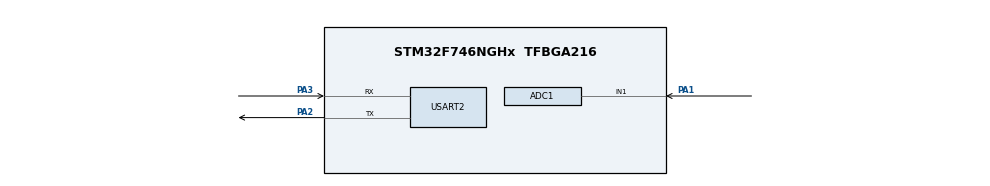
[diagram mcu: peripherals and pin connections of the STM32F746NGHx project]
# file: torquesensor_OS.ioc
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ADC1.Channel-0\#ChannelRegularConversion=ADC_CHANNEL_1
ADC1.NbrOfConversionFlag=1
ADC1.Rank-0\#ChannelRegularConversion=1
ADC1.SamplingTime-0\#ChannelRegularConversion=ADC_SAMPLETIME_3CYCLES
ADC1.master=1
FREERTOS.BinarySemaphores01=myBinarySem01,Dynamic,NULL
FREERTOS.Queues01=xTorqueSensorQueue,10,float,0,Dynamic,NULL,NULL
FREERTOS.Tasks01=vTaskReadTorque,0,128,TaskReadTorqueSensor,Default,NULL,Dynamic,NULL,NULL;vTaskMain,0,128,TaskMain,Default,NULL,Dynamic,NULL,NULL
Mcu.Family=STM32F7
Mcu.Name=STM32F746NGHx
Mcu.Package=TFBGA216
NVIC.PriorityGroup=NVIC_PRIORITYGROUP_4
PA1.Signal=ADCx_IN1
PA2.Mode=Asynchronous
PA2.Signal=USART2_TX
PA3.Mode=Asynchronous
PA3.Signal=USART2_RX
ProjectManager.HeapSize=0x200
ProjectManager.StackSize=0x400
ProjectManager.TargetToolchain=STM32CubeIDE
RCC.HSE_VALUE=25000000
RCC.HSI_VALUE=16000000
RCC.LSE_VALUE=32768
RCC.USBFreq_Value=96000000
RCC.VCOOutputFreq_Value=192000000
SH.ADCx_IN1.0=ADC1_IN1,IN1
USART2.VirtualMode-Asynchronous=VM_ASYNC
VP_FREERTOS_VS_CMSIS_V1.Mode=CMSIS_V1
board=custom

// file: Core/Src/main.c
/* USER CODE BEGIN Header */
/**
  ******************************************************************************
  * @file           : main.c
  * @brief          : Main program body
  ******************************************************************************
  * @attention
  *
  * Copyright (c) 2024 STMicroelectronics.
  * All rights reserved.
  *
  * This software is licensed under terms that can be found in the LICENSE file
  * in the root directory of this software component.
  * If no LICENSE file comes with this software, it is provided AS-IS.
  *
  ******************************************************************************
  */
/* USER CODE END Header */
#include "main.h"
#include "cmsis_os.h"
#include <stdio.h>
#include <string.h>

ADC_HandleTypeDef hadc1;

UART_HandleTypeDef huart2;

osThreadId vTaskReadTorqueHandle;
osThreadId vTaskMainHandle;
osMessageQId xTorqueSensorQueueHandle;
osSemaphoreId myBinarySem01Handle;

void SystemClock_Config(void);
static void MPU_Config(void);
static void MX_GPIO_Init(void);
static void MX_ADC1_Init(void);
static void MX_USART2_UART_Init(void);
void TaskReadTorqueSensor(void const * argument);
void TaskMain(void const * argument);

int main(void)
{

  /* MPU Configuration--------------------------------------------------------*/
  MPU_Config();

  /* MCU Configuration--------------------------------------------------------*/

  /* Reset of all peripherals, Initializes the Flash interface and the Systick. */
  HAL_Init();

  /* Configure the system clock */
  SystemClock_Config();

  /* Initialize all configured peripherals */
  MX_GPIO_Init();
  MX_ADC1_Init();
  MX_USART2_UART_Init();

  /* Create the semaphores(s) */
  /* definition and creation of myBinarySem01 */
  osSemaphoreDef(myBinarySem01);
  myBinarySem01Handle = osSemaphoreCreate(osSemaphore(myBinarySem01), 1);

  /* Create the queue(s) */
  /* definition and creation of xTorqueSensorQueue */
  osMessageQDef(xTorqueSensorQueue, 10, float);
  xTorqueSensorQueueHandle = osMessageCreate(osMessageQ(xTorqueSensorQueue), NULL);

  /* Create the thread(s) */
  /* definition and creation of vTaskReadTorque */
  osThreadDef(vTaskReadTorque, TaskReadTorqueSensor, osPriorityNormal, 0, 128);
  vTaskReadTorqueHandle = osThreadCreate(osThread(vTaskReadTorque), NULL);

  /* definition and creation of vTaskMain */
  osThreadDef(vTaskMain, TaskMain, osPriorityNormal, 0, 128);
  vTaskMainHandle = osThreadCreate(osThread(vTaskMain), NULL);

  /* Start scheduler */
  osKernelStart();

  /* We should never get here as control is now taken by the scheduler */
  /* Infinite loop */
  while (1)
  {

  }
}

void SystemClock_Config(void)
{
  RCC_OscInitTypeDef RCC_OscInitStruct = {0};
  RCC_ClkInitTypeDef RCC_ClkInitStruct = {0};

  /** Configure the main internal regulator output voltage
  */
  __HAL_RCC_PWR_CLK_ENABLE();
  __HAL_PWR_VOLTAGESCALING_CONFIG(PWR_REGULATOR_VOLTAGE_SCALE3);

  /** Initializes the RCC Oscillators according to the specified parameters
  * in the RCC_OscInitTypeDef structure.
  */
  RCC_OscInitStruct.OscillatorType = RCC_OSCILLATORTYPE_HSI;
  RCC_OscInitStruct.HSIState = RCC_HSI_ON;
  RCC_OscInitStruct.HSICalibrationValue = RCC_HSICALIBRATION_DEFAULT;
  RCC_OscInitStruct.PLL.PLLState = RCC_PLL_NONE;
  if (HAL_RCC_OscConfig(&RCC_OscInitStruct) != HAL_OK)
  {
    Error_Handler();
  }

  /** Initializes the CPU, AHB and APB buses clocks
  */
  RCC_ClkInitStruct.ClockType = RCC_CLOCKTYPE_HCLK|RCC_CLOCKTYPE_SYSCLK
                              |RCC_CLOCKTYPE_PCLK1|RCC_CLOCKTYPE_PCLK2;
  RCC_ClkInitStruct.SYSCLKSource = RCC_SYSCLKSOURCE_HSI;
  RCC_ClkInitStruct.AHBCLKDivider = RCC_SYSCLK_DIV1;
  RCC_ClkInitStruct.APB1CLKDivider = RCC_HCLK_DIV1;
  RCC_ClkInitStruct.APB2CLKDivider = RCC_HCLK_DIV1;

  if (HAL_RCC_ClockConfig(&RCC_ClkInitStruct, FLASH_LATENCY_0) != HAL_OK)
  {
    Error_Handler();
  }
}

static void MX_ADC1_Init(void)
{

  ADC_ChannelConfTypeDef sConfig = {0};

  /** Configure the global features of the ADC (Clock, Resolution, Data Alignment and number of conversion)
  */
  hadc1.Instance = ADC1;
  hadc1.Init.ClockPrescaler = ADC_CLOCK_SYNC_PCLK_DIV2;
  hadc1.Init.Resolution = ADC_RESOLUTION_12B;
  hadc1.Init.ScanConvMode = ADC_SCAN_DISABLE;
  hadc1.Init.ContinuousConvMode = DISABLE;
  hadc1.Init.DiscontinuousConvMode = DISABLE;
  hadc1.Init.ExternalTrigConvEdge = ADC_EXTERNALTRIGCONVEDGE_NONE;
  hadc1.Init.ExternalTrigConv = ADC_SOFTWARE_START;
  hadc1.Init.DataAlign = ADC_DATAALIGN_RIGHT;
  hadc1.Init.NbrOfConversion = 1;
  hadc1.Init.DMAContinuousRequests = DISABLE;
  hadc1.Init.EOCSelection = ADC_EOC_SINGLE_CONV;
  if (HAL_ADC_Init(&hadc1) != HAL_OK)
  {
    Error_Handler();
  }

  /** Configure for the selected ADC regular channel its corresponding rank in the sequencer and its sample time.
  */
  sConfig.Channel = ADC_CHANNEL_1;
  sConfig.Rank = ADC_REGULAR_RANK_1;
  sConfig.SamplingTime = ADC_SAMPLETIME_3CYCLES;
  if (HAL_ADC_ConfigChannel(&hadc1, &sConfig) != HAL_OK)
  {
    Error_Handler();
  }

}

static void MX_USART2_UART_Init(void)
{

  huart2.Instance = USART2;
  huart2.Init.BaudRate = 115200;
  huart2.Init.WordLength = UART_WORDLENGTH_8B;
  huart2.Init.StopBits = UART_STOPBITS_1;
  huart2.Init.Parity = UART_PARITY_NONE;
  huart2.Init.Mode = UART_MODE_TX_RX;
  huart2.Init.HwFlowCtl = UART_HWCONTROL_NONE;
  huart2.Init.OverSampling = UART_OVERSAMPLING_16;
  huart2.Init.OneBitSampling = UART_ONE_BIT_SAMPLE_DISABLE;
  huart2.AdvancedInit.AdvFeatureInit = UART_ADVFEATURE_NO_INIT;
  if (HAL_UART_Init(&huart2) != HAL_OK)
  {
    Error_Handler();
  }

}

static void MX_GPIO_Init(void)
{

  /* GPIO Ports Clock Enable */
  __HAL_RCC_GPIOA_CLK_ENABLE();

}

void TaskReadTorqueSensor(void const * argument)
{
  /* USER CODE BEGIN 5 */
  /* Infinite loop */
	  uint16_t adcValue;
	  float torqueValue;

	  for (;;) {
	    if (HAL_ADC_Start(&hadc1) != HAL_OK) {
	      // Handle ADC start error
	      continue;
	    }

	    if (HAL_ADC_PollForConversion(&hadc1, portMAX_DELAY) != HAL_OK) {
	      // Handle ADC conversion error or timeout
	      continue;
	    }

	    adcValue = HAL_ADC_GetValue(&hadc1);

	    // Convert ADC value to torque value (replace with your conversion logic)
	    torqueValue = (float)adcValue * (10.0f / 4095.0f);

	    xQueueSend(xTorqueSensorQueueHandle, &torqueValue, portMAX_DELAY);

	    xSemaphoreGive(myBinarySem01Handle);

	    vTaskDelay(pdMS_TO_TICKS(1000)); // Delay for 1000ms (1 second)
	  }
	}

  /* USER CODE END 5 */

void TaskMain(void const * argument)
{
  /* USER CODE BEGIN TaskMain */
  /* Infinite loop */
	float receivedTorqueValue;

	  for (;;) {
	    xSemaphoreTake(myBinarySem01Handle, portMAX_DELAY);

	    if (xQueueReceive(xTorqueSensorQueueHandle, &receivedTorqueValue, portMAX_DELAY) == pdTRUE) {
	      char uartTxBuffer[50];
	      snprintf(uartTxBuffer, sizeof(uartTxBuffer), "Torque Value: %.2f Nm\r\n", receivedTorqueValue);
	      HAL_UART_Transmit(&huart2, (uint8_t *)uartTxBuffer, strlen(uartTxBuffer), HAL_MAX_DELAY);
	    }
	  }
  /* USER CODE END TaskMain */
}

/* MPU Configuration */

void MPU_Config(void)
{
  MPU_Region_InitTypeDef MPU_InitStruct = {0};

  /* Disables the MPU */
  HAL_MPU_Disable();

  /** Initializes and configures the Region and the memory to be protected
  */
  MPU_InitStruct.Enable = MPU_REGION_ENABLE;
  MPU_InitStruct.Number = MPU_REGION_NUMBER0;
  MPU_InitStruct.BaseAddress = 0x0;
  MPU_InitStruct.Size = MPU_REGION_SIZE_4GB;
  MPU_InitStruct.SubRegionDisable = 0x87;
  MPU_InitStruct.TypeExtField = MPU_TEX_LEVEL0;
  MPU_InitStruct.AccessPermission = MPU_REGION_NO_ACCESS;
  MPU_InitStruct.DisableExec = MPU_INSTRUCTION_ACCESS_DISABLE;
  MPU_InitStruct.IsShareable = MPU_ACCESS_SHAREABLE;
  MPU_InitStruct.IsCacheable = MPU_ACCESS_NOT_CACHEABLE;
  MPU_InitStruct.IsBufferable = MPU_ACCESS_NOT_BUFFERABLE;

  HAL_MPU_ConfigRegion(&MPU_InitStruct);
  /* Enables the MPU */
  HAL_MPU_Enable(MPU_PRIVILEGED_DEFAULT);

}

void Error_Handler(void)
{
  __disable_irq();
  while (1)
  {
  }
}
